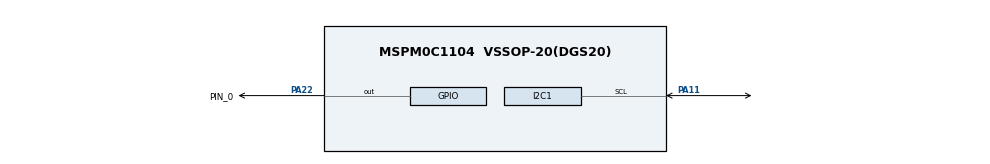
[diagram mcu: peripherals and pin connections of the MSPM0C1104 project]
//@cliArgs --device "MSPM0C110X" --package "VSSOP-20(DGS20)" --part "Default"
//@v2CliArgs --device "MSPM0C1104" --package "VSSOP-20(DGS20)"
// @cliArgs --board /ti/boards/LP_MSPM0C1104 --rtos nortos

/**
 * Import the modules used in this configuration.
 */
const GPIO          = scripting.addModule("/ti/driverlib/GPIO", {}, false);
const GPIO1         = GPIO.addInstance();
const GPIO2         = GPIO.addInstance();
const I2C           = scripting.addModule("/ti/driverlib/I2C", {}, false);
const I2C1          = I2C.addInstance();
const SYSCTL        = scripting.addModule("/ti/driverlib/SYSCTL");
const ProjectConfig = scripting.addModule("/ti/project_config/ProjectConfig");

/**
 * Write custom configuration values to the imported modules.
 */
GPIO1.$name                              = "GPIO_SWITCHES";
GPIO1.associatedPins[0].assignedPin      = "16";
GPIO1.associatedPins[0].$name            = "USER_SWITCH_1";
GPIO1.associatedPins[0].direction        = "INPUT";
GPIO1.associatedPins[0].internalResistor = "PULL_UP";
GPIO1.associatedPins[0].interruptEn      = true;
GPIO1.associatedPins[0].assignedPort     = "PORTA";
GPIO1.associatedPins[0].polarity         = "FALL";

const Board = scripting.addModule("/ti/driverlib/Board", {}, false);

GPIO2.$name                          = "GPIO_LED";
GPIO2.associatedPins[0].$name        = "PIN_0";
GPIO2.associatedPins[0].initialValue = "SET";
GPIO2.associatedPins[0].pin.$assign  = "PA22";

I2C1.basicEnableTarget                 = true;
I2C1.basicTargetAddress                = 0x48;
I2C1.intTarget                         = ["RXFIFO_TRIGGER"];
I2C1.$name                             = "I2C";
I2C1.peripheral.sclPin.$assign         = "PA11";

SYSCTL.clockTreeEn = true;

ProjectConfig.genLinker  = false;
ProjectConfig.genStartup = false;
scripting.suppress("All four File Generation options must be enabled in order to guarantee Device Migration support\\. If an option is disabled, the user must manually configure that setting on its own file\\.", ProjectConfig);
